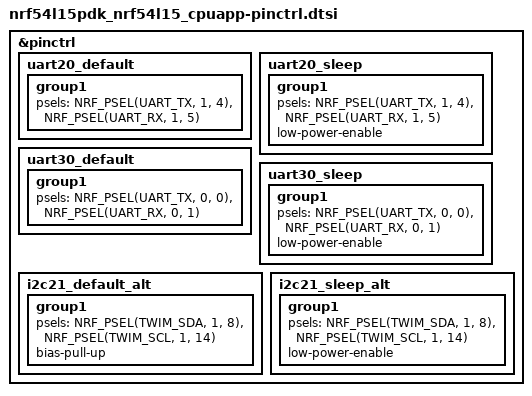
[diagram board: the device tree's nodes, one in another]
/*
 * Copyright (c) 2024 Nordic Semiconductor
 * SPDX-License-Identifier: Apache-2.0
 */

&pinctrl {
	uart20_default: uart20_default {
		group1 {
			psels = <NRF_PSEL(UART_TX, 1, 4)>,
				<NRF_PSEL(UART_RX, 1, 5)>;
		};
	};

	uart20_sleep: uart20_sleep {
		group1 {
			psels = <NRF_PSEL(UART_TX, 1, 4)>,
				<NRF_PSEL(UART_RX, 1, 5)>;
			low-power-enable;
		};
	};

	uart30_default: uart30_default {
		group1 {
			psels = <NRF_PSEL(UART_TX, 0, 0)>,
				<NRF_PSEL(UART_RX, 0, 1)>;
		};
	};

	uart30_sleep: uart30_sleep {
		group1 {
			psels = <NRF_PSEL(UART_TX, 0, 0)>,
				<NRF_PSEL(UART_RX, 0, 1)>;
			low-power-enable;
		};
	};

	i2c21_default_alt: i2c21_default_alt {
		group1 {
			psels = <NRF_PSEL(TWIM_SDA, 1, 8)>,
				<NRF_PSEL(TWIM_SCL, 1, 14)>;
			bias-pull-up;
		};
	};

	i2c21_sleep_alt: i2c21_sleep_alt {
		group1 {
			psels = <NRF_PSEL(TWIM_SDA, 1, 8)>,
				<NRF_PSEL(TWIM_SCL, 1, 14)>;
			low-power-enable;
		};
	};
};
